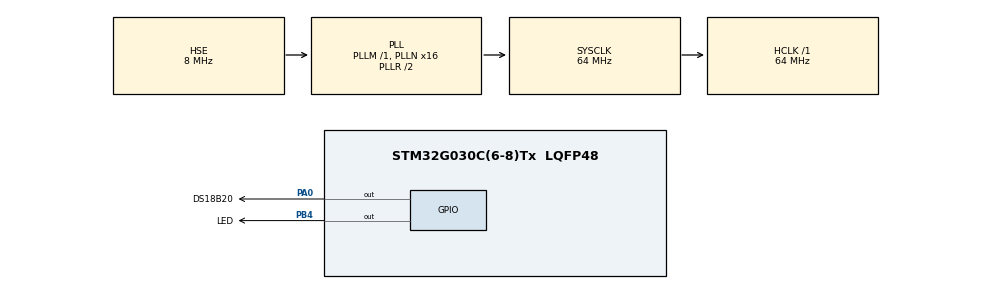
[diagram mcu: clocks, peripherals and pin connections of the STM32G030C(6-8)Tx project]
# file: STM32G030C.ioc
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Mcu.Family=STM32G0
Mcu.Name=STM32G030C(6-8)Tx
Mcu.Package=LQFP48
PA0.GPIO_Label=DS18B20
PA0.Signal=GPIO_Output
PA13.Mode=Serial_Wire
PA13.Signal=SYS_SWDIO
PA14-BOOT0.Mode=Serial_Wire
PA14-BOOT0.Signal=SYS_SWCLK
PB4.GPIO_Label=LED
PB4.Signal=GPIO_Output
PF0-OSC_IN\ (PF0).Mode=HSE-External-Oscillator
PF0-OSC_IN\ (PF0).Signal=RCC_OSC_IN
PF1-OSC_OUT\ (PF1).Mode=HSE-External-Oscillator
PF1-OSC_OUT\ (PF1).Signal=RCC_OSC_OUT
ProjectManager.HeapSize=0x200
ProjectManager.StackSize=0x400
ProjectManager.TargetToolchain=MDK-ARM V5.27
RCC.ADCFreq_Value=64000000
RCC.AHBFreq_Value=64000000
RCC.CortexFreq_Value=64000000
RCC.EXTERNAL_CLOCK_VALUE=12288000
RCC.HCLKFreq_Value=64000000
RCC.HSE_VALUE=8000000
RCC.HSI_VALUE=16000000
RCC.LSE_VALUE=32768
RCC.PLLN=16
RCC.PLLSourceVirtual=RCC_PLLSOURCE_HSE
RCC.SYSCLKFreq_VALUE=64000000
RCC.SYSCLKSource=RCC_SYSCLKSOURCE_PLLCLK
RCC.VCOOutputFreq_Value=128000000
TIM1.Prescaler=63
VP_TIM1_VS_ClockSourceINT.Mode=Internal
board=custom

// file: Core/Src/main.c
/* USER CODE BEGIN Header */
/**
  ******************************************************************************
  * @file           : main.c
  * @brief          : Main program body
  ******************************************************************************
  * @attention
  *
  * <h2><center>&copy; Copyright (c) 2021 STMicroelectronics.
  * All rights reserved.</center></h2>
  *
  * This software component is licensed by ST under BSD 3-Clause license,
  * the "License"; You may not use this file except in compliance with the
  * License. You may obtain a copy of the License at:
  *                        opensource.org/licenses/BSD-3-Clause
  *
  ******************************************************************************
  */
/* USER CODE END Header */
#include "main.h"
#include "tim.h"
#include "gpio.h"

/* USER CODE BEGIN Includes */
#include "ds18b20.h"
/* USER CODE END Includes */

void SystemClock_Config(void);

int main(void)
{

  /* MCU Configuration--------------------------------------------------------*/

  /* Reset of all peripherals, Initializes the Flash interface and the Systick. */
  HAL_Init();

  /* USER CODE BEGIN Init */
	float buff=0;
  /* USER CODE END Init */

  /* Configure the system clock */
  SystemClock_Config();

  /* Initialize all configured peripherals */
  MX_GPIO_Init();
  MX_TIM1_Init();
  /* USER CODE BEGIN 2 */
	Ds18b20_Init();
  /* USER CODE END 2 */

  /* Infinite loop */
  while (1)
  {

    /* USER CODE BEGIN 3 */
		HAL_Delay(500);
		Ds18b20_ManualConvert();
		buff = ds18b20[0].Temperature;
		if(buff>25) HAL_GPIO_TogglePin(LED_GPIO_Port,LED_Pin);
  }
  /* USER CODE END 3 */
}

void SystemClock_Config(void)
{
  RCC_OscInitTypeDef RCC_OscInitStruct = {0};
  RCC_ClkInitTypeDef RCC_ClkInitStruct = {0};

  /** Configure the main internal regulator output voltage
  */
  HAL_PWREx_ControlVoltageScaling(PWR_REGULATOR_VOLTAGE_SCALE1);
  /** Initializes the RCC Oscillators according to the specified parameters
  * in the RCC_OscInitTypeDef structure.
  */
  RCC_OscInitStruct.OscillatorType = RCC_OSCILLATORTYPE_HSE;
  RCC_OscInitStruct.HSEState = RCC_HSE_ON;
  RCC_OscInitStruct.PLL.PLLState = RCC_PLL_ON;
  RCC_OscInitStruct.PLL.PLLSource = RCC_PLLSOURCE_HSE;
  RCC_OscInitStruct.PLL.PLLM = RCC_PLLM_DIV1;
  RCC_OscInitStruct.PLL.PLLN = 16;
  RCC_OscInitStruct.PLL.PLLP = RCC_PLLP_DIV2;
  RCC_OscInitStruct.PLL.PLLR = RCC_PLLR_DIV2;
  if (HAL_RCC_OscConfig(&RCC_OscInitStruct) != HAL_OK)
  {
    Error_Handler();
  }
  /** Initializes the CPU, AHB and APB buses clocks
  */
  RCC_ClkInitStruct.ClockType = RCC_CLOCKTYPE_HCLK|RCC_CLOCKTYPE_SYSCLK
                              |RCC_CLOCKTYPE_PCLK1;
  RCC_ClkInitStruct.SYSCLKSource = RCC_SYSCLKSOURCE_PLLCLK;
  RCC_ClkInitStruct.AHBCLKDivider = RCC_SYSCLK_DIV1;
  RCC_ClkInitStruct.APB1CLKDivider = RCC_HCLK_DIV1;

  if (HAL_RCC_ClockConfig(&RCC_ClkInitStruct, FLASH_LATENCY_2) != HAL_OK)
  {
    Error_Handler();
  }
}

void Error_Handler(void)
{
  __disable_irq();
  while (1)
  {
  }
}

/************************ (C) COPYRIGHT STMicroelectronics *****END OF FILE****/
